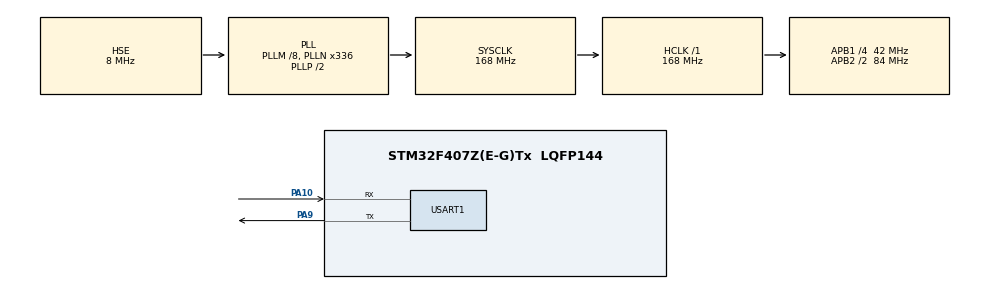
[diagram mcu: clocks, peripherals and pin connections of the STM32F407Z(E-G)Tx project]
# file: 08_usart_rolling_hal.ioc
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Mcu.Family=STM32F4
Mcu.Name=STM32F407Z(E-G)Tx
Mcu.Package=LQFP144
NVIC.PriorityGroup=NVIC_PRIORITYGROUP_4
PA10.Mode=Asynchronous
PA10.Signal=USART1_RX
PA13.Mode=Serial_Wire
PA13.Signal=SYS_JTMS-SWDIO
PA14.Mode=Serial_Wire
PA14.Signal=SYS_JTCK-SWCLK
PA9.Mode=Asynchronous
PA9.Signal=USART1_TX
PC14-OSC32_IN.Mode=LSE-External-Oscillator
PC14-OSC32_IN.Signal=RCC_OSC32_IN
PC15-OSC32_OUT.Mode=LSE-External-Oscillator
PC15-OSC32_OUT.Signal=RCC_OSC32_OUT
PH0-OSC_IN.Mode=HSE-External-Oscillator
PH0-OSC_IN.Signal=RCC_OSC_IN
PH1-OSC_OUT.Mode=HSE-External-Oscillator
PH1-OSC_OUT.Signal=RCC_OSC_OUT
ProjectManager.HeapSize=0x200
ProjectManager.StackSize=0x400
ProjectManager.TargetToolchain=MDK-ARM V5.32
RCC.48MHZClocksFreq_Value=84000000
RCC.AHBFreq_Value=168000000
RCC.APB1CLKDivider=RCC_HCLK_DIV4
RCC.APB1Freq_Value=42000000
RCC.APB1TimFreq_Value=84000000
RCC.APB2CLKDivider=RCC_HCLK_DIV2
RCC.APB2Freq_Value=84000000
RCC.APB2TimFreq_Value=168000000
RCC.CortexFreq_Value=168000000
RCC.HCLKFreq_Value=168000000
RCC.HSE_VALUE=8000000
RCC.HSI_VALUE=16000000
RCC.PLLM=8
RCC.PLLN=336
RCC.PLLSourceVirtual=RCC_PLLSOURCE_HSE
RCC.SYSCLKFreq_VALUE=168000000
RCC.SYSCLKSource=RCC_SYSCLKSOURCE_PLLCLK
RCC.VCOOutputFreq_Value=336000000
USART1.VirtualMode=VM_ASYNC
board=custom

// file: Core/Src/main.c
/* USER CODE BEGIN Header */
/**
  ******************************************************************************
  * @file           : main.c
  * @brief          : Main program body
  ******************************************************************************
  * @attention
  *
  * <h2><center>&copy; Copyright (c) 2025 STMicroelectronics.
  * All rights reserved.</center></h2>
  *
  * This software component is licensed by ST under BSD 3-Clause license,
  * the "License"; You may not use this file except in compliance with the
  * License. You may obtain a copy of the License at:
  *                        opensource.org/licenses/BSD-3-Clause
  *
  ******************************************************************************
  */
/* USER CODE END Header */
#include "main.h"
#include "usart.h"
#include "gpio.h"

/* USER CODE BEGIN Includes */
#include "string.h"
/* USER CODE END Includes */

void SystemClock_Config(void);

/* USER CODE BEGIN 0 */
uint8_t buffer[100] = {0};
uint16_t size =0;

/* USER CODE END 0 */

int main(void)
{

  /* MCU Configuration--------------------------------------------------------*/

  /* Reset of all peripherals, Initializes the Flash interface and the Systick. */
  HAL_Init();

  /* Configure the system clock */
  SystemClock_Config();

  /* Initialize all configured peripherals */
  MX_GPIO_Init();
  MX_USART1_UART_Init();
  /* USER CODE BEGIN 2 */

  //发送一个字符串
      HAL_UART_Transmit(&huart1,"hello,world\n",13,1000);//注意每个参数
//    uint8_t str[14] = "hello,world\n";
//    HAL_UART_Transmit(&huart1,str,strlen((char*)str),100);
//
//    uint8_t str1 = 'A';
//    HAL_UART_Transmit(&huart1,&str1,1,100);

  /* USER CODE END 2 */

  /* Infinite loop */
  while (1)
  {

    /* USER CODE BEGIN 3 */
      //1.阻塞式,接收定长数据并且发送出去,我们用下边的两个函数,第三个参数是指定的数量,
      //如果收10个,发14个,发的会用buffer中的10个之后的初始化解释发送
      if(HAL_UART_Receive(&huart1,buffer,10,1000)==HAL_OK)
      {
        HAL_UART_Transmit(&huart1,buffer,10,1000);
      }
      //这样的操作方式接收和发送的数据一定要定长,否则就会出现部分乱码

//    //接收定长字符串,然后原样回去
//  先收再发,你接收的定长字符串需要一个接收缓冲区buffer(全局,存放接收到的数据)
//      if(HAL_UART_Receive(&huart1,buffer,10,1000) == HAL_OK)//如果接收完成hal会返回一个枚举值
//      {
//            HAL_UART_Transmit(&huart1,buffer,10,1000);
//      }

      //2.接收变长字符串,然后原样回去
//HAL_StatusTypeDef HAL_UARTEx_ReceiveToIdle(UART_HandleTypeDef *huart, uint8_t *pData, uint16_t Size, uint16_t *RxLen, uint32_t Timeout)
//第三个参数填入缓冲区的大小(想要的大小),第四个参数由系统计算出具体接收到的数据的长度(实际的大小)
      if(HAL_UARTEx_ReceiveToIdle(&huart1,buffer,100,&size,1000) == HAL_OK)//如果接收完成hal会返回一个枚举值
      {
            HAL_UART_Transmit(&huart1,buffer,size,1000);
      }

  }
  /* USER CODE END 3 */
}

void SystemClock_Config(void)
{
  RCC_OscInitTypeDef RCC_OscInitStruct = {0};
  RCC_ClkInitTypeDef RCC_ClkInitStruct = {0};

  /** Configure the main internal regulator output voltage
  */
  __HAL_RCC_PWR_CLK_ENABLE();
  __HAL_PWR_VOLTAGESCALING_CONFIG(PWR_REGULATOR_VOLTAGE_SCALE1);
  /** Initializes the RCC Oscillators according to the specified parameters
  * in the RCC_OscInitTypeDef structure.
  */
  RCC_OscInitStruct.OscillatorType = RCC_OSCILLATORTYPE_HSE;
  RCC_OscInitStruct.HSEState = RCC_HSE_ON;
  RCC_OscInitStruct.PLL.PLLState = RCC_PLL_ON;
  RCC_OscInitStruct.PLL.PLLSource = RCC_PLLSOURCE_HSE;
  RCC_OscInitStruct.PLL.PLLM = 8;
  RCC_OscInitStruct.PLL.PLLN = 336;
  RCC_OscInitStruct.PLL.PLLP = RCC_PLLP_DIV2;
  RCC_OscInitStruct.PLL.PLLQ = 4;
  if (HAL_RCC_OscConfig(&RCC_OscInitStruct) != HAL_OK)
  {
    Error_Handler();
  }
  /** Initializes the CPU, AHB and APB buses clocks
  */
  RCC_ClkInitStruct.ClockType = RCC_CLOCKTYPE_HCLK|RCC_CLOCKTYPE_SYSCLK
                              |RCC_CLOCKTYPE_PCLK1|RCC_CLOCKTYPE_PCLK2;
  RCC_ClkInitStruct.SYSCLKSource = RCC_SYSCLKSOURCE_PLLCLK;
  RCC_ClkInitStruct.AHBCLKDivider = RCC_SYSCLK_DIV1;
  RCC_ClkInitStruct.APB1CLKDivider = RCC_HCLK_DIV4;
  RCC_ClkInitStruct.APB2CLKDivider = RCC_HCLK_DIV2;

  if (HAL_RCC_ClockConfig(&RCC_ClkInitStruct, FLASH_LATENCY_5) != HAL_OK)
  {
    Error_Handler();
  }
}

void Error_Handler(void)
{
  __disable_irq();
  while (1)
  {
  }
}

/************************ (C) COPYRIGHT STMicroelectronics *****END OF FILE****/
